# LPC5516 register map
Vendor: nxp.com; File version: 1.0
CPU: CM33 r2p0, little endian, MPU, FPU, VTOR, 3 interrupt priority bits
Registers are 32-bit, read-write, reset 0x0 unless marked. A register's access mark holds for its fields unless they carry their own. Offsets are from the block's base; [hi:lo] are bit positions.

## FLEXCOMM0 — Flexcomm serial communication
Base 0x40086000
Same registers: FLEXCOMM1 0x40087000, FLEXCOMM2 0x40088000, FLEXCOMM3 0x40089000, FLEXCOMM4 0x4008A000, FLEXCOMM5 0x40096000, FLEXCOMM6 0x40097000, FLEXCOMM7 0x40098000, FLEXCOMM8 0x4009F000
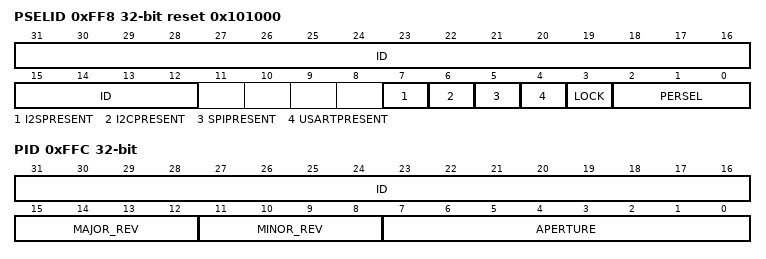
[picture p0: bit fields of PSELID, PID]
0xFF8 PSELID reset 0x101000 — Peripheral Select and Flexcomm ID register.
  [31:12] ID ro — Flexcomm ID.
  [7] I2SPRESENT ro — I 2S present indicator. This field is Read-only.
    0=NOT_PRESENT (This Flexcomm does not include the I2S function.); 1=PRESENT (This Flexcomm includes the I2S function.)
  [6] I2CPRESENT ro — I2C present indicator. This field is Read-only.
    0=NOT_PRESENT (This Flexcomm does not include the I2C function.); 1=PRESENT (This Flexcomm includes the I2C function.)
  [5] SPIPRESENT ro — SPI present indicator. This field is Read-only.
    0=NOT_PRESENT (This Flexcomm does not include the SPI function.); 1=PRESENT (This Flexcomm includes the SPI function.)
  [4] USARTPRESENT ro — USART present indicator. This field is Read-only.
    0=NOT_PRESENT (This Flexcomm does not include the USART function.); 1=PRESENT (This Flexcomm includes the USART function.)
  [3] LOCK — Lock the peripheral select. This field is writable by software.
    0=UNLOCKED (Peripheral select can be changed by software.); 1=LOCKED (Peripheral select is locked and cannot be changed until this Flexcomm or the entire device is reset.)
  [2:0] PERSEL — Peripheral Select. This field is writable by software.
    0=NO_PERIPH_SELECTED (No peripheral selected.); 1=USART (USART function selected.); 2=SPI (SPI function selected.); 3=I2C (I2C function selected.); 4=I2S_TRANSMIT (I2S transmit function selected.); 5=I2S_RECEIVE (I2S receive function selected.)
0xFFC PID ro — Peripheral identification register.
  [31:16] ID — Module identifier for the selected function.
  [15:12] MAJOR_REV — Major revision of module implementation.
  [11:8] MINOR_REV — Minor revision of module implementation.
  [7:0] APERTURE — size aperture for the register port on the bus (APB or AHB).

## CRC_ENGINE
Base 0x40095000
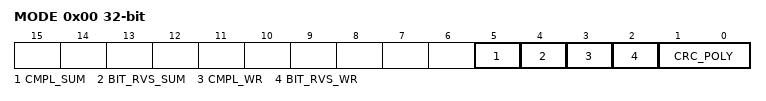
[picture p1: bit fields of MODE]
0x00 MODE — CRC mode register
  [5] CMPL_SUM — CRC sum complement: 1 = 1's complement for CRC_SUM 0 = No 1's complement for CRC_SUM
  [4] BIT_RVS_SUM — CRC sum bit order: 1 = Bit order reverse for CRC_SUM 0 = No bit order reverse for CRC_SUM
  [3] CMPL_WR — Data complement: 1 = 1's complement for CRC_WR_DATA 0 = No 1's complement for CRC_WR_DATA
  [2] BIT_RVS_WR — Data bit order: 1 = Bit order reverse for CRC_WR_DATA (per byte) 0 = No bit order reverse for CRC_WR_DATA (per byte)
  [1:0] CRC_POLY — CRC polynomial: 1X = CRC-32 polynomial 01 = CRC-16 polynomial 00 = CRC-CCITT polynomial
0x04 SEED reset 0xFFFF — CRC seed register
  [31:0] CRC_SEED — A write access to this register will load CRC seed value to CRC_SUM register with selected bit order and 1's complement pre-processes. A write access to this register will overrule the CRC calculation in progresses.
0x08 SUM ro reset 0xFFFF (SUM_WR_DATA view) — CRC checksum register
  [31:0] CRC_SUM — The most recent CRC sum can be read through this register with selected bit order and 1's complement post-processes.
0x08 WR_DATA wo reset not defined (SUM_WR_DATA view) — CRC data register
  [31:0] CRC_WR_DATA — Data written to this register will be taken to perform CRC calculation with selected bit order and 1's complement pre-process. Any write size 8, 16 or 32-bit are allowed and accept back-to-back transactions.

## DBGMAILBOX — MCU Debugger Mailbox
Base 0x4009C000
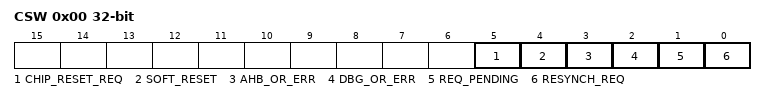
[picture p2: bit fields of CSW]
0x00 CSW — CRC mode register
  [5] CHIP_RESET_REQ wo — Write only bit. Once written will cause the chip to reset (note that the DM is not reset by this reset as it is only resettable by a SOFT reset or a POR/BOD event)
  [4] SOFT_RESET — Soft Reset for DM (write-only from AHB, not readable and selfclearing). A write to this bit will cause a soft reset for DM.
  [3] AHB_OR_ERR — AHB overrun Error (Return value overwritten by ROM)
  [2] DBG_OR_ERR — Debugger overrun error (previous REQUEST overwritten before being picked up by ROM)
  [1] REQ_PENDING — Request is pending from debugger (i.e unread value in REQUEST)
  [0] RESYNCH_REQ — Debugger will set this bit to 1 to request a resynchronrisation
0x04 REQUEST reset 0xFFFF — CRC seed register
  [31:0] REQ — Request Value
0x08 RETURN — Return value from ROM.
  [31:0] RET — The Return value from ROM.
0xFC ID ro reset 0x2A0000 — Identification register
  [31:0] ID — Identification value.

## Notices in the file
Copyright 2016-2020 NXP
All rights reserved.
SPDX-License-Identifier: BSD-3-Clause
